# HC32A4A8RITJ register map
File version: 1.0
CPU: CM4 r0p1, little endian, MPU, FPU, 4 interrupt priority bits
Registers are 32-bit, read-write, reset 0x0 unless marked. A register's access mark holds for its fields unless they carry their own. Offsets are from the block's base; [hi:lo] are bit positions; {n}, {i} and the like mark numbered series.

## EMB0 — desc EMB
Base 0x40017C00
Same registers: EMB1 0x40017C20, EMB2 0x40017C40, EMB3 0x40017C60
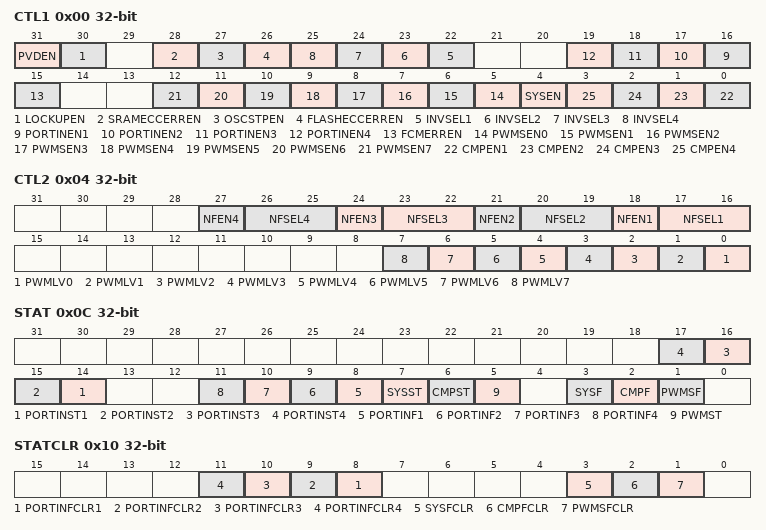
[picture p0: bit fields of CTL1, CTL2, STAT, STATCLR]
0x00 CTL1
  [31] PVDEN, [30] LOCKUPEN, [28] SRAMECCERREN, [27] OSCSTPEN, [26] FLASHECCERREN, [n+21] INVSEL{n} (n=1..4), [n+15] PORTINEN{n} (n=1..4), [15] FCMERREN, [n+5] PWMSEN{n} (n=0..7), [4] SYSEN, [n-1] CMPEN{n} (n=1..4)
0x04 CTL2
  [3n+15] NFEN{n} (n=1..4), [3n+14:3n+13] NFSEL{n} (n=1..4), [n] PWMLV{n} (n=0..7)
0x08 SOE
  [0] SOE
0x0C STAT ro
  [n+13] PORTINST{n} (n=1..4), [n+7] PORTINF{n} (n=1..4), [7] SYSST, [6] CMPST, [5] PWMST, [3] SYSF, [2] CMPF, [1] PWMSF
0x10 STATCLR wo
  [n+7] PORTINFCLR{n} (n=1..4), [3] SYSFCLR, [2] CMPFCLR, [1] PWMSFCLR
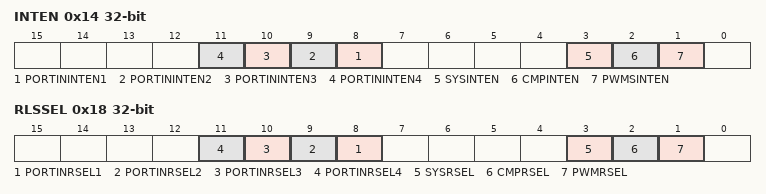
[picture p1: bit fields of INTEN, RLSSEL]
0x14 INTEN
  [n+7] PORTININTEN{n} (n=1..4), [3] SYSINTEN, [2] CMPINTEN, [1] PWMSINTEN
0x18 RLSSEL
  [n+7] PORTINRSEL{n} (n=1..4), [3] SYSRSEL, [2] CMPRSEL, [1] PWMRSEL

## EMB4 — desc EMB
Base 0x40017C80
Same registers: EMB5 0x40017CA0, EMB6 0x40017CC0
Registers as EMB0; these are added or differ:
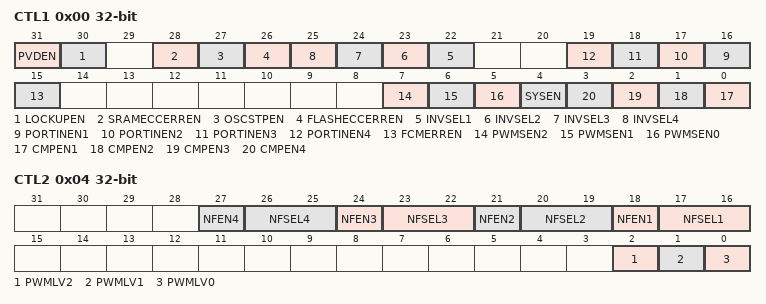
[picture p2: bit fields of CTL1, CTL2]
0x00 CTL1
  [31] PVDEN, [30] LOCKUPEN, [28] SRAMECCERREN, [27] OSCSTPEN, [26] FLASHECCERREN, [n+21] INVSEL{n} (n=1..4), [n+15] PORTINEN{n} (n=1..4), [15] FCMERREN, [7] PWMSEN2, [6] PWMSEN1, [5] PWMSEN0, [4] SYSEN, [n-1] CMPEN{n} (n=1..4)
0x04 CTL2
  [3n+15] NFEN{n} (n=1..4), [3n+14:3n+13] NFSEL{n} (n=1..4), [2] PWMLV2, [1] PWMLV1, [0] PWMLV0

## ERMU
Base 0x40048800
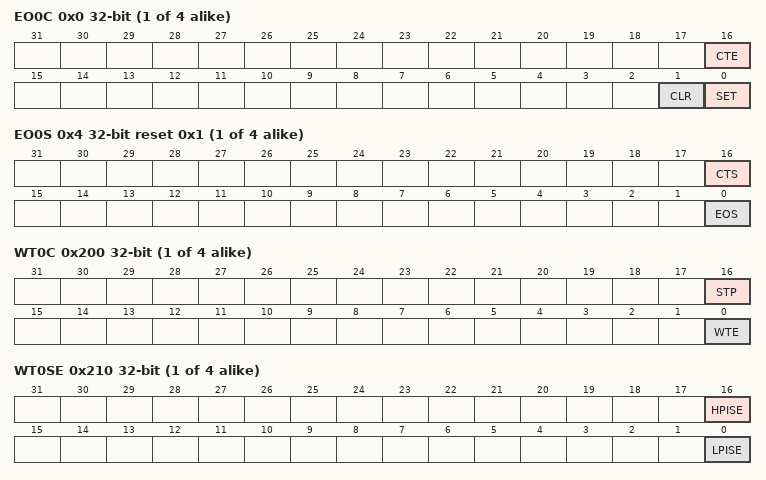
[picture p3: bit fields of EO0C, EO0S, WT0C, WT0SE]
{0x0+0x80*i} EO{i}C (i=0..3)
  [16] CTE, [1] CLR wo, [0] SET wo
{0x4+0x80*i} EO{i}S ro reset 0x1 (i=0..3)
  [16] CTS, [0] EOS wo
{0x8+0x80*i} EO{i}CTCNT ro (i=0..3)
  [15:0] CNT
{0xC+0x80*i} EO{i}CTCMP (i=0..3)
  [15:0] CMP
{0x10+0x80*i} EO{i}TTC (i=0..3)
  [0] TTE
{0x18+0x80*i} EO{i}TTCMP (i=0..3)
  [15:0] CMP
{0x40+0x80*i} EO{i}OM0 (i=0..3)
  [31:0] OM
{0x44+0x80*i} EO{i}OM1 (i=0..3)
  [31:0] OM
{0x200+0x20*i} WT{i}C (i=0..3)
  [16] STP wo, [0] WTE
{0x204+0x20*i} WT{i}S ro (i=0..3)
  [0] WTS
{0x208+0x20*i} WT{i}CNT ro (i=0..3)
  [15:0] CNT
{0x20C+0x20*i} WT{i}CMP (i=0..3)
  [15:0] CMP
{0x210+0x20*i} WT{i}SE (i=0..3)
  [16] HPISE, [0] LPISE
0x300 ESS0 ro
  [31:0] ESS
0x304 ESS1 ro
  [31:0] ESS
0x340 ESSC0 wo
  [31:0] ESSC
0x344 ESSC1 wo
  [31:0] ESSC
0x380 PET0 wo
  [31:0] PET
0x384 PET1 wo
  [31:0] PET
0x3C0 RE0
  [31:0] RE
0x3C4 RE1
  [31:0] RE
0x400 LPIE0
  [31:0] LPIE
0x404 LPIE1
  [31:0] LPIE
0x500 HPIE0
  [31:0] HPIE
0x504 HPIE1
  [31:0] HPIE
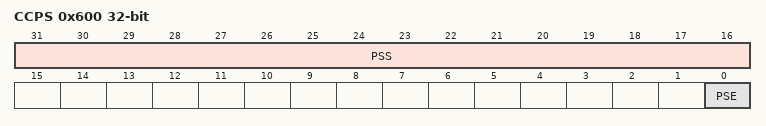
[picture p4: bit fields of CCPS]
0x600 CCPS
  [31:16] PSS, [0] PSE

## FCM1 — desc FCM
Base 0x40048400
Same registers: FCM2 0x40048440, FCM3 0x40048480, FCM4 0x400484C0
0x00 LVR
  [15:0] LVR
0x04 UVR
  [15:0] UVR
0x08 CNTR ro
  [15:0] CNTR
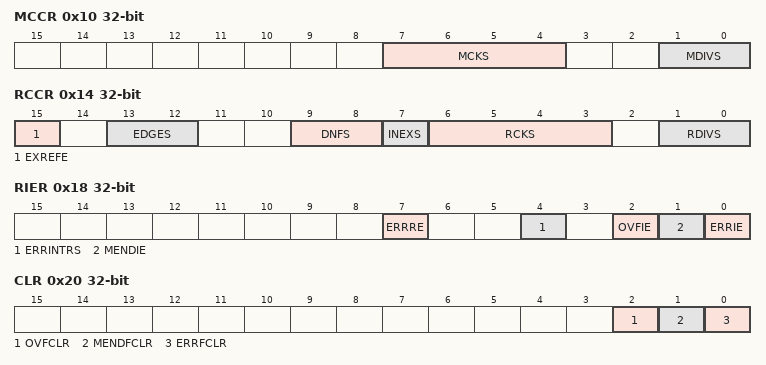
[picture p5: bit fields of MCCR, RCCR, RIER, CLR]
0x10 MCCR
  [7:4] MCKS, [1:0] MDIVS
0x14 RCCR
  [15] EXREFE, [13:12] EDGES, [9:8] DNFS, [7] INEXS, [6:3] RCKS, [1:0] RDIVS
0x18 RIER
  [7] ERRRE, [4] ERRINTRS, [2] OVFIE, [1] MENDIE, [0] ERRIE
0x20 CLR wo
  [2] OVFCLR, [1] MENDFCLR, [0] ERRFCLR

## FCM_COM
Base 0x40048400; alternate view of FCM1
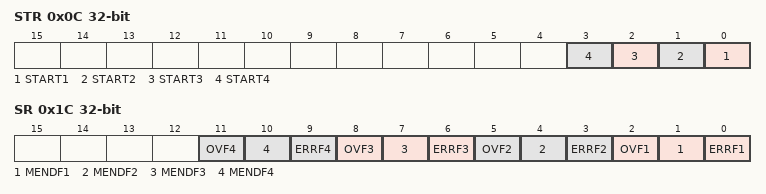
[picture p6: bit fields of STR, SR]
0x0C STR
  [n-1] START{n} (n=1..4)
0x1C SR ro
  [3n-1] OVF{n} (n=1..4), [3n-2] MENDF{n} (n=1..4), [3n-3] ERRF{n} (n=1..4)

## FMAC1 — desc FMAC
Base 0x40058000
Same registers: FMAC2 0x40058400, FMAC3 0x40058800, FMAC4 0x40058C00
0x00 ENR
  [0] FMACEN
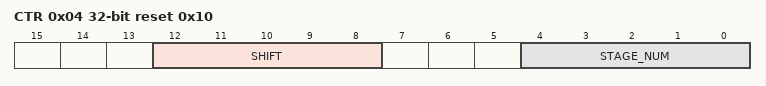
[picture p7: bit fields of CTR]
0x04 CTR reset 0x10
  [12:8] SHIFT, [4:0] STAGE_NUM
0x08 IER
  [0] INTEN
0x0C DTR
  [15:0] DIN
0x10 RTR0
0x14 RTR1
0x18 STR
  [31] READY
{0x20+4i} COR{i} (i=0..16)
  [15:0] CIN

## HASH
Base 0x40008400
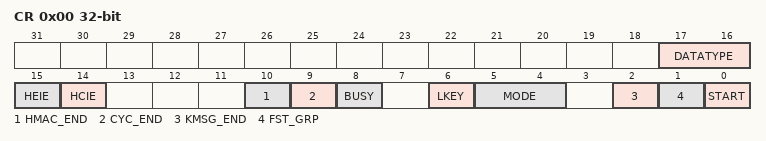
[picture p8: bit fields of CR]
0x00 CR
  [17:16] DATATYPE, [15] HEIE, [14] HCIE, [10] HMAC_END, [9] CYC_END, [8] BUSY, [6] LKEY, [5:4] MODE, [2] KMSG_END, [1] FST_GRP, [0] START
0x10 HR7
0x14 HR6
0x18 HR5
0x1C HR4
0x20 HR3
0x24 HR2
0x28 HR1
0x2C HR0
0x40 DR15
0x44 DR14
0x48 DR13
0x4C DR12
0x50 DR11
0x54 DR10
0x58 DR9
0x5C DR8
0x60 DR7
0x64 DR6
0x68 DR5
0x6C DR4
0x70 DR3
0x74 DR2
0x78 DR1
0x7C DR0
